# SIMPLE_MCU register map
Vendor: Example Corp; Series: Simple Series; File version: 1.0
Simple MCU Example
CPU: CM4 r0p1, little endian, no MPU, FPU, 4 interrupt priority bits
Registers are 32-bit, read-write, reset 0x0 unless marked. A register's access mark holds for its fields unless they carry their own. Offsets are from the block's base; lines under a group give offsets from that group; [hi:lo] are bit positions; {n}, {i} and the like mark numbered series; 'fields as' and 'values as' point back to an identical list; <NAME> marks a mode.

## Memory map
0x40013800 UART size 0x400 — Universal Asynchronous Receiver Transmitter
0x40020000 GPIO size 0x400 — General Purpose I/O
0x50000000 TEST — Test peripheral with edge cases

## GPIO — General Purpose I/O
Base 0x40020000
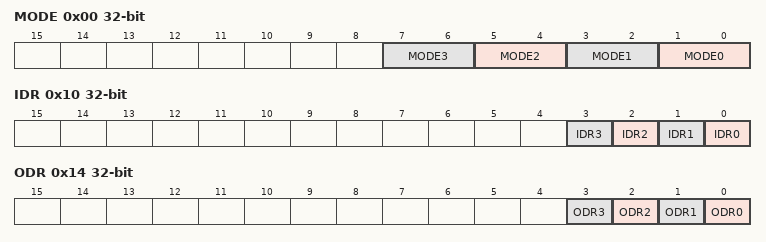
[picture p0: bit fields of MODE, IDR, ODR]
0x00 MODE — GPIO Mode Register
  [2n+1:2n] MODE{n} (n=0..3) — Pin {n} mode
0x10 IDR ro — GPIO Input Data Register
  [n] IDR{n} (n=0..3) — Pin {n} input
0x14 ODR — GPIO Output Data Register
  [n] ODR{n} (n=0..3) — Pin {n} output

## UART — Universal Asynchronous Receiver Transmitter
Base 0x40013800
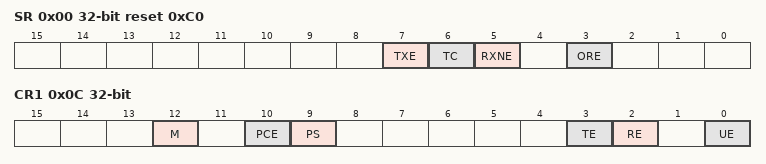
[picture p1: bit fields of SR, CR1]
0x00 SR reset 0xC0 — Status Register
  [7] TXE ro — Transmit data register empty
  [6] TC ro — Transmission complete
  [5] RXNE ro — Read data register not empty
  [3] ORE ro — Overrun error
0x04 DR — Data Register
  [8:0] DR — Data value
0x0C CR1 — Control Register 1
  [12] M — Word length
  [10] PCE — Parity control enable
  [9] PS — Parity selection
  [3] TE — Transmitter enable
  [2] RE — Receiver enable
  [0] UE — UART Enable

## TEST — Test peripheral with edge cases
Base 0x50000000
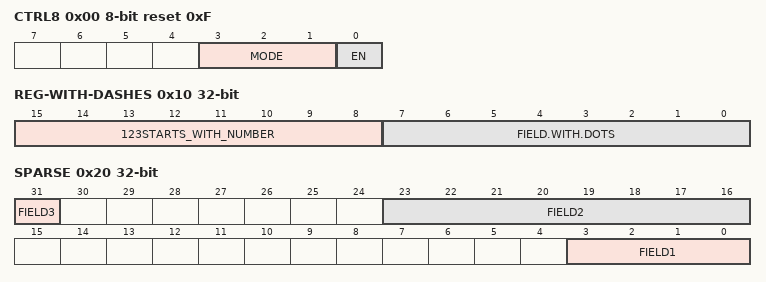
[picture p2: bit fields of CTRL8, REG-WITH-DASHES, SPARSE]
0x00 CTRL8 8-bit reset 0xF — 8-bit control register
  [3:1] MODE — Mode selection
  [0] EN — Enable bit
0x02 STATUS16 16-bit reset 0x8000 — 16-bit status register
  [15] READY ro — Ready flag
  [15:8] ERROR ro — Error flags
0x10 REG-WITH-DASHES — Register with dashes in name
  [15:8] 123STARTS_WITH_NUMBER — Field starting with number
  [7:0] FIELD.WITH.DOTS
0x20 SPARSE — Register with sparse bit fields
  [31] FIELD3 — Third field
  [23:16] FIELD2 — Second field
  [3:0] FIELD1 — First field

## Licence text in the file
Commercial License
